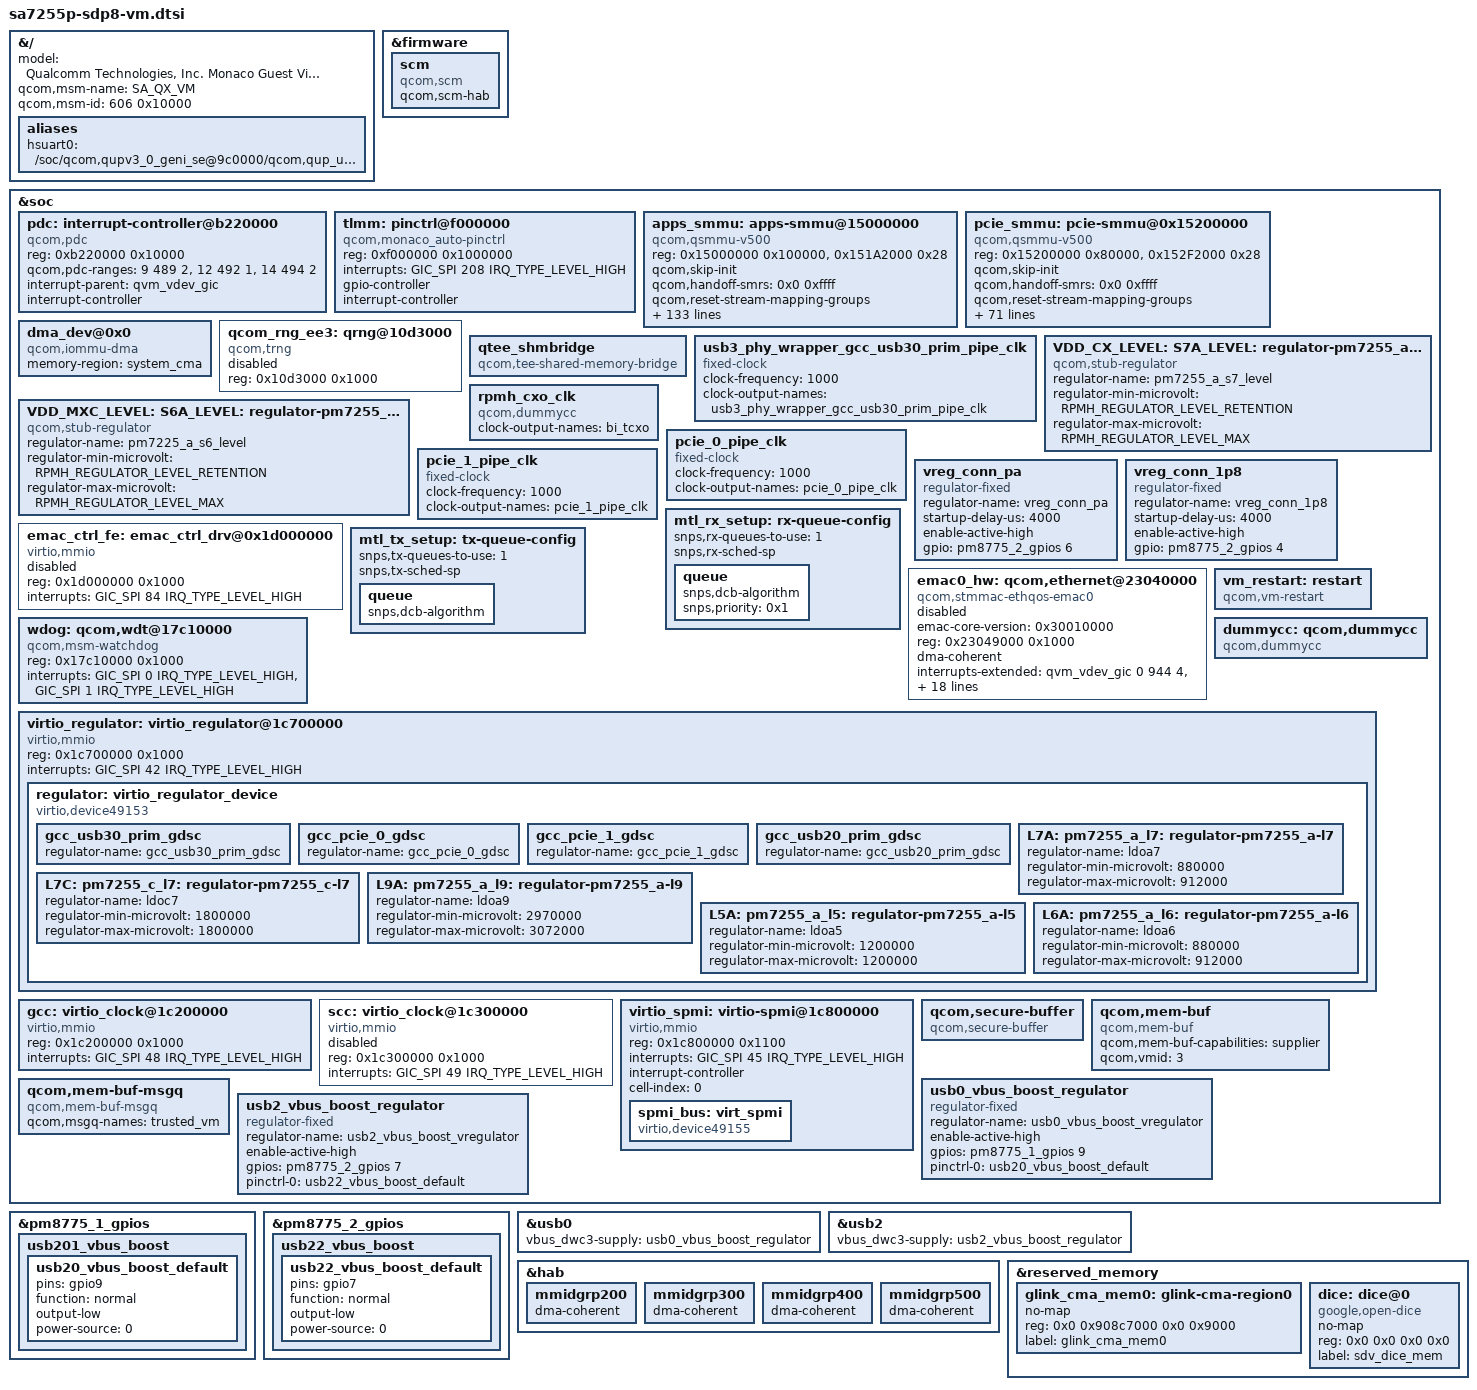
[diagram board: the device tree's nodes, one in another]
// SPDX-License-Identifier: BSD-3-Clause
/*
 * Copyright (c) Qualcomm Technologies, Inc. and/or its subsidiaries.
 */
#include "sdp8-quin-vm-common.dtsi"
#include <dt-bindings/soc/qcom,ipcc.h>

&{/} {
	model = "Qualcomm Technologies, Inc. Monaco Guest Virtual Machine";
	qcom,msm-name  = "SA_QX_VM";
	qcom,msm-id = <606 0x10000>;

	aliases {
		hsuart0 = "/soc/qcom,qupv3_0_geni_se@9c0000/qcom,qup_uart@988000";
	};
};

&firmware {
	scm: scm {
		compatible = "qcom,scm";
		qcom,scm-hab;
	};
};

&soc {
	pdc: interrupt-controller@b220000 {
		compatible = "qcom,pdc";
		reg = <0xb220000 0x10000>;
		qcom,pdc-ranges = <9 489 2>, <12 492 1>, <14 494 2>;
		#interrupt-cells = <2>;
		interrupt-parent = <&qvm_vdev_gic>;
		interrupt-controller;
	};

	tlmm: pinctrl@f000000 {
		compatible = "qcom,monaco_auto-pinctrl";
		reg = <0xf000000 0x1000000>;
		interrupts = <GIC_SPI 208 IRQ_TYPE_LEVEL_HIGH>;
		gpio-controller;
		#gpio-cells = <2>;
		interrupt-controller;
		#interrupt-cells = <2>;
	};

	apps_smmu: apps-smmu@15000000 {
		compatible = "qcom,qsmmu-v500";
		reg = <0x15000000 0x100000>,
			<0x151A2000 0x28>;
		reg-names = "base", "tcu-base";
		#iommu-cells = <2>;
		qcom,skip-init;
		qcom,handoff-smrs = <0x0 0xffff>;
		qcom,reset-stream-mapping-groups;
		qcom,multi-match-handoff-smr;
		qcom,use-3-lvl-tables;
		#global-interrupts = <2>;
		#size-cells = <1>;
		#address-cells = <1>;
		ranges;
		interrupts =	<GIC_SPI 119 IRQ_TYPE_LEVEL_HIGH>,
				<GIC_SPI 120 IRQ_TYPE_LEVEL_HIGH>,
				<GIC_SPI  98 IRQ_TYPE_LEVEL_HIGH>,
				<GIC_SPI  99 IRQ_TYPE_LEVEL_HIGH>,
				<GIC_SPI 100 IRQ_TYPE_LEVEL_HIGH>,
				<GIC_SPI 101 IRQ_TYPE_LEVEL_HIGH>,
				<GIC_SPI 102 IRQ_TYPE_LEVEL_HIGH>,
				<GIC_SPI 103 IRQ_TYPE_LEVEL_HIGH>,
				<GIC_SPI 104 IRQ_TYPE_LEVEL_HIGH>,
				<GIC_SPI 105 IRQ_TYPE_LEVEL_HIGH>,
				<GIC_SPI 106 IRQ_TYPE_LEVEL_HIGH>,
				<GIC_SPI 107 IRQ_TYPE_LEVEL_HIGH>,
				<GIC_SPI 108 IRQ_TYPE_LEVEL_HIGH>,
				<GIC_SPI 109 IRQ_TYPE_LEVEL_HIGH>,
				<GIC_SPI 110 IRQ_TYPE_LEVEL_HIGH>,
				<GIC_SPI 111 IRQ_TYPE_LEVEL_HIGH>,
				<GIC_SPI 112 IRQ_TYPE_LEVEL_HIGH>,
				<GIC_SPI 113 IRQ_TYPE_LEVEL_HIGH>,
				<GIC_SPI 114 IRQ_TYPE_LEVEL_HIGH>,
				<GIC_SPI 115 IRQ_TYPE_LEVEL_HIGH>,
				<GIC_SPI 116 IRQ_TYPE_LEVEL_HIGH>,
				<GIC_SPI 117 IRQ_TYPE_LEVEL_HIGH>,
				<GIC_SPI 118 IRQ_TYPE_LEVEL_HIGH>,
				<GIC_SPI 181 IRQ_TYPE_LEVEL_HIGH>,
				<GIC_SPI 182 IRQ_TYPE_LEVEL_HIGH>,
				<GIC_SPI 183 IRQ_TYPE_LEVEL_HIGH>,
				<GIC_SPI 184 IRQ_TYPE_LEVEL_HIGH>,
				<GIC_SPI 185 IRQ_TYPE_LEVEL_HIGH>,
				<GIC_SPI 186 IRQ_TYPE_LEVEL_HIGH>,
				<GIC_SPI 187 IRQ_TYPE_LEVEL_HIGH>,
				<GIC_SPI 188 IRQ_TYPE_LEVEL_HIGH>,
				<GIC_SPI 189 IRQ_TYPE_LEVEL_HIGH>,
				<GIC_SPI 190 IRQ_TYPE_LEVEL_HIGH>,
				<GIC_SPI 191 IRQ_TYPE_LEVEL_HIGH>,
				<GIC_SPI 192 IRQ_TYPE_LEVEL_HIGH>,
				<GIC_SPI 315 IRQ_TYPE_LEVEL_HIGH>,
				<GIC_SPI 316 IRQ_TYPE_LEVEL_HIGH>,
				<GIC_SPI 317 IRQ_TYPE_LEVEL_HIGH>,
				<GIC_SPI 318 IRQ_TYPE_LEVEL_HIGH>,
				<GIC_SPI 319 IRQ_TYPE_LEVEL_HIGH>,
				<GIC_SPI 320 IRQ_TYPE_LEVEL_HIGH>,
				<GIC_SPI 321 IRQ_TYPE_LEVEL_HIGH>,
				<GIC_SPI 322 IRQ_TYPE_LEVEL_HIGH>,
				<GIC_SPI 323 IRQ_TYPE_LEVEL_HIGH>,
				<GIC_SPI 324 IRQ_TYPE_LEVEL_HIGH>,
				<GIC_SPI 325 IRQ_TYPE_LEVEL_HIGH>,
				<GIC_SPI 326 IRQ_TYPE_LEVEL_HIGH>,
				<GIC_SPI 327 IRQ_TYPE_LEVEL_HIGH>,
				<GIC_SPI 328 IRQ_TYPE_LEVEL_HIGH>,
				<GIC_SPI 329 IRQ_TYPE_LEVEL_HIGH>,
				<GIC_SPI 330 IRQ_TYPE_LEVEL_HIGH>,
				<GIC_SPI 331 IRQ_TYPE_LEVEL_HIGH>,
				<GIC_SPI 332 IRQ_TYPE_LEVEL_HIGH>,
				<GIC_SPI 333 IRQ_TYPE_LEVEL_HIGH>,
				<GIC_SPI 334 IRQ_TYPE_LEVEL_HIGH>,
				<GIC_SPI 335 IRQ_TYPE_LEVEL_HIGH>,
				<GIC_SPI 336 IRQ_TYPE_LEVEL_HIGH>,
				<GIC_SPI 337 IRQ_TYPE_LEVEL_HIGH>,
				<GIC_SPI 338 IRQ_TYPE_LEVEL_HIGH>,
				<GIC_SPI 339 IRQ_TYPE_LEVEL_HIGH>,
				<GIC_SPI 340 IRQ_TYPE_LEVEL_HIGH>,
				<GIC_SPI 341 IRQ_TYPE_LEVEL_HIGH>,
				<GIC_SPI 342 IRQ_TYPE_LEVEL_HIGH>,
				<GIC_SPI 343 IRQ_TYPE_LEVEL_HIGH>,
				<GIC_SPI 344 IRQ_TYPE_LEVEL_HIGH>,
				<GIC_SPI 345 IRQ_TYPE_LEVEL_HIGH>,
				<GIC_SPI 395 IRQ_TYPE_LEVEL_HIGH>,
				<GIC_SPI 396 IRQ_TYPE_LEVEL_HIGH>,
				<GIC_SPI 397 IRQ_TYPE_LEVEL_HIGH>,
				<GIC_SPI 398 IRQ_TYPE_LEVEL_HIGH>,
				<GIC_SPI 399 IRQ_TYPE_LEVEL_HIGH>,
				<GIC_SPI 400 IRQ_TYPE_LEVEL_HIGH>,
				<GIC_SPI 401 IRQ_TYPE_LEVEL_HIGH>,
				<GIC_SPI 402 IRQ_TYPE_LEVEL_HIGH>,
				<GIC_SPI 403 IRQ_TYPE_LEVEL_HIGH>,
				<GIC_SPI 404 IRQ_TYPE_LEVEL_HIGH>,
				<GIC_SPI 405 IRQ_TYPE_LEVEL_HIGH>,
				<GIC_SPI 406 IRQ_TYPE_LEVEL_HIGH>,
				<GIC_SPI 407 IRQ_TYPE_LEVEL_HIGH>,
				<GIC_SPI 408 IRQ_TYPE_LEVEL_HIGH>,
				<GIC_SPI 409 IRQ_TYPE_LEVEL_HIGH>,
				<GIC_SPI 418 IRQ_TYPE_LEVEL_HIGH>,
				<GIC_SPI 419 IRQ_TYPE_LEVEL_HIGH>,
				<GIC_SPI 412 IRQ_TYPE_LEVEL_HIGH>,
				<GIC_SPI 421 IRQ_TYPE_LEVEL_HIGH>,
				<GIC_SPI 706 IRQ_TYPE_LEVEL_HIGH>,
				<GIC_SPI 423 IRQ_TYPE_LEVEL_HIGH>,
				<GIC_SPI 424 IRQ_TYPE_LEVEL_HIGH>,
				<GIC_SPI 425 IRQ_TYPE_LEVEL_HIGH>,
				<GIC_SPI 689 IRQ_TYPE_LEVEL_HIGH>,
				<GIC_SPI 690 IRQ_TYPE_LEVEL_HIGH>,
				<GIC_SPI 691 IRQ_TYPE_LEVEL_HIGH>,
				<GIC_SPI 692 IRQ_TYPE_LEVEL_HIGH>,
				<GIC_SPI 693 IRQ_TYPE_LEVEL_HIGH>,
				<GIC_SPI 694 IRQ_TYPE_LEVEL_HIGH>,
				<GIC_SPI 695 IRQ_TYPE_LEVEL_HIGH>,
				<GIC_SPI 696 IRQ_TYPE_LEVEL_HIGH>,
				<GIC_SPI 410 IRQ_TYPE_LEVEL_HIGH>,
				<GIC_SPI 411 IRQ_TYPE_LEVEL_HIGH>,
				<GIC_SPI 420 IRQ_TYPE_LEVEL_HIGH>,
				<GIC_SPI 413 IRQ_TYPE_LEVEL_HIGH>,
				<GIC_SPI 422 IRQ_TYPE_LEVEL_HIGH>,
				<GIC_SPI 707 IRQ_TYPE_LEVEL_HIGH>,
				<GIC_SPI 708 IRQ_TYPE_LEVEL_HIGH>,
				<GIC_SPI 709 IRQ_TYPE_LEVEL_HIGH>,
				<GIC_SPI 710 IRQ_TYPE_LEVEL_HIGH>,
				<GIC_SPI 711 IRQ_TYPE_LEVEL_HIGH>,
				<GIC_SPI 414 IRQ_TYPE_LEVEL_HIGH>,
				<GIC_SPI 712 IRQ_TYPE_LEVEL_HIGH>,
				<GIC_SPI 713 IRQ_TYPE_LEVEL_HIGH>,
				<GIC_SPI 714 IRQ_TYPE_LEVEL_HIGH>,
				<GIC_SPI 715 IRQ_TYPE_LEVEL_HIGH>,
				<GIC_SPI 912 IRQ_TYPE_LEVEL_HIGH>,
				<GIC_SPI 911 IRQ_TYPE_LEVEL_HIGH>,
				<GIC_SPI 910 IRQ_TYPE_LEVEL_HIGH>,
				<GIC_SPI 909 IRQ_TYPE_LEVEL_HIGH>,
				<GIC_SPI 908 IRQ_TYPE_LEVEL_HIGH>,
				<GIC_SPI 907 IRQ_TYPE_LEVEL_HIGH>,
				<GIC_SPI 906 IRQ_TYPE_LEVEL_HIGH>,
				<GIC_SPI 905 IRQ_TYPE_LEVEL_HIGH>,
				<GIC_SPI 904 IRQ_TYPE_LEVEL_HIGH>,
				<GIC_SPI 903 IRQ_TYPE_LEVEL_HIGH>,
				<GIC_SPI 902 IRQ_TYPE_LEVEL_HIGH>,
				<GIC_SPI 901 IRQ_TYPE_LEVEL_HIGH>,
				<GIC_SPI 900 IRQ_TYPE_LEVEL_HIGH>,
				<GIC_SPI 899 IRQ_TYPE_LEVEL_HIGH>,
				<GIC_SPI 898 IRQ_TYPE_LEVEL_HIGH>,
				<GIC_SPI 897 IRQ_TYPE_LEVEL_HIGH>,
				<GIC_SPI 896 IRQ_TYPE_LEVEL_HIGH>,
				<GIC_SPI 895 IRQ_TYPE_LEVEL_HIGH>;
		};

	pcie_smmu: pcie-smmu@0x15200000 {
		compatible = "qcom,qsmmu-v500";
		reg = <0x15200000 0x80000>,
			<0x152F2000 0x28>;
		reg-names = "base", "tcu-base";
		#iommu-cells = <2>;
		qcom,skip-init;
		qcom,handoff-smrs = <0x0 0xffff>;
		qcom,reset-stream-mapping-groups;
		qcom,multi-match-handoff-smr;
		qcom,use-3-lvl-tables;
		qcom,split-tables;
		#global-interrupts = <2>;
		#size-cells = <1>;
		#address-cells = <1>;
		#tcu-testbus-version = <1>;
		ranges;

		interrupts =	<GIC_SPI 920 IRQ_TYPE_LEVEL_HIGH>,
				<GIC_SPI 921 IRQ_TYPE_LEVEL_HIGH>,
				<GIC_SPI 925 IRQ_TYPE_LEVEL_HIGH>,
				<GIC_SPI 926 IRQ_TYPE_LEVEL_HIGH>,
				<GIC_SPI 927 IRQ_TYPE_LEVEL_HIGH>,
				<GIC_SPI 928 IRQ_TYPE_LEVEL_HIGH>,
				<GIC_SPI 950 IRQ_TYPE_LEVEL_HIGH>,
				<GIC_SPI 951 IRQ_TYPE_LEVEL_HIGH>,
				<GIC_SPI 952 IRQ_TYPE_LEVEL_HIGH>,
				<GIC_SPI 953 IRQ_TYPE_LEVEL_HIGH>,
				<GIC_SPI 954 IRQ_TYPE_LEVEL_HIGH>,
				<GIC_SPI 955 IRQ_TYPE_LEVEL_HIGH>,
				<GIC_SPI 956 IRQ_TYPE_LEVEL_HIGH>,
				<GIC_SPI 957 IRQ_TYPE_LEVEL_HIGH>,
				<GIC_SPI 958 IRQ_TYPE_LEVEL_HIGH>,
				<GIC_SPI 885 IRQ_TYPE_LEVEL_HIGH>,
				<GIC_SPI 886 IRQ_TYPE_LEVEL_HIGH>,
				<GIC_SPI 887 IRQ_TYPE_LEVEL_HIGH>,
				<GIC_SPI 888 IRQ_TYPE_LEVEL_HIGH>,
				<GIC_SPI 820 IRQ_TYPE_LEVEL_HIGH>,
				<GIC_SPI 822 IRQ_TYPE_LEVEL_HIGH>,
				<GIC_SPI 823 IRQ_TYPE_LEVEL_HIGH>,
				<GIC_SPI 310 IRQ_TYPE_LEVEL_HIGH>,
				<GIC_SPI 446 IRQ_TYPE_LEVEL_HIGH>,
				<GIC_SPI 447 IRQ_TYPE_LEVEL_HIGH>,
				<GIC_SPI 452 IRQ_TYPE_LEVEL_HIGH>,
				<GIC_SPI 840 IRQ_TYPE_LEVEL_HIGH>,
				<GIC_SPI 841 IRQ_TYPE_LEVEL_HIGH>,
				<GIC_SPI 842 IRQ_TYPE_LEVEL_HIGH>,
				<GIC_SPI 843 IRQ_TYPE_LEVEL_HIGH>,
				<GIC_SPI 844 IRQ_TYPE_LEVEL_HIGH>,
				<GIC_SPI 845 IRQ_TYPE_LEVEL_HIGH>,
				<GIC_SPI 846 IRQ_TYPE_LEVEL_HIGH>,
				<GIC_SPI 847 IRQ_TYPE_LEVEL_HIGH>,
				<GIC_SPI 848 IRQ_TYPE_LEVEL_HIGH>,
				<GIC_SPI 849 IRQ_TYPE_LEVEL_HIGH>,
				<GIC_SPI 802 IRQ_TYPE_LEVEL_HIGH>,
				<GIC_SPI 803 IRQ_TYPE_LEVEL_HIGH>,
				<GIC_SPI 804 IRQ_TYPE_LEVEL_HIGH>,
				<GIC_SPI 805 IRQ_TYPE_LEVEL_HIGH>,
				<GIC_SPI 806 IRQ_TYPE_LEVEL_HIGH>,
				<GIC_SPI 807 IRQ_TYPE_LEVEL_HIGH>,
				<GIC_SPI 808 IRQ_TYPE_LEVEL_HIGH>,
				<GIC_SPI 809 IRQ_TYPE_LEVEL_HIGH>,
				<GIC_SPI 810 IRQ_TYPE_LEVEL_HIGH>,
				<GIC_SPI 811 IRQ_TYPE_LEVEL_HIGH>,
				<GIC_SPI 812 IRQ_TYPE_LEVEL_HIGH>,
				<GIC_SPI 813 IRQ_TYPE_LEVEL_HIGH>,
				<GIC_SPI 814 IRQ_TYPE_LEVEL_HIGH>,
				<GIC_SPI 836 IRQ_TYPE_LEVEL_HIGH>,
				<GIC_SPI 837 IRQ_TYPE_LEVEL_HIGH>,
				<GIC_SPI 838 IRQ_TYPE_LEVEL_HIGH>,
				<GIC_SPI 839 IRQ_TYPE_LEVEL_HIGH>,
				<GIC_SPI 854 IRQ_TYPE_LEVEL_HIGH>,
				<GIC_SPI 855 IRQ_TYPE_LEVEL_HIGH>,
				<GIC_SPI 856 IRQ_TYPE_LEVEL_HIGH>,
				<GIC_SPI 790 IRQ_TYPE_LEVEL_HIGH>,
				<GIC_SPI 791 IRQ_TYPE_LEVEL_HIGH>,
				<GIC_SPI 792 IRQ_TYPE_LEVEL_HIGH>,
				<GIC_SPI 793 IRQ_TYPE_LEVEL_HIGH>,
				<GIC_SPI 794 IRQ_TYPE_LEVEL_HIGH>,
				<GIC_SPI 795 IRQ_TYPE_LEVEL_HIGH>,
				<GIC_SPI 796 IRQ_TYPE_LEVEL_HIGH>,
				<GIC_SPI 639 IRQ_TYPE_LEVEL_HIGH>,
				<GIC_SPI 79 IRQ_TYPE_LEVEL_HIGH>,
				<GIC_SPI 640 IRQ_TYPE_LEVEL_HIGH>;
	};

	dma_dev@0x0 {
		compatible = "qcom,iommu-dma";
		memory-region = <&system_cma>;
	};

	qcom_rng_ee3: qrng@10d3000 {
		compatible = "qcom,trng";
		reg = <0x10d3000 0x1000>;
		status = "disabled";
	};

	qtee_shmbridge: qtee_shmbridge {
		compatible = "qcom,tee-shared-memory-bridge";
	};

	usb3_phy_wrapper_gcc_usb30_prim_pipe_clk: usb3_phy_wrapper_gcc_usb30_prim_pipe_clk {
		compatible = "fixed-clock";
		clock-frequency = <1000>;
		clock-output-names = "usb3_phy_wrapper_gcc_usb30_prim_pipe_clk";
		#clock-cells = <0>;
	};

	VDD_CX_LEVEL: S7A_LEVEL:
		pm7255_a_s7_level: regulator-pm7255_a-s7-level {
			compatible = "qcom,stub-regulator";
			regulator-name = "pm7255_a_s7_level";
			regulator-min-microvolt =
				<RPMH_REGULATOR_LEVEL_RETENTION>;
			regulator-max-microvolt =
				<RPMH_REGULATOR_LEVEL_MAX>;
	};

	VDD_MXC_LEVEL: S6A_LEVEL:
		pm7255_a_s6_level: regulator-pm7255_a-s6-level {
			compatible = "qcom,stub-regulator";
			regulator-name = "pm7225_a_s6_level";
			regulator-min-microvolt =
				<RPMH_REGULATOR_LEVEL_RETENTION>;
			regulator-max-microvolt =
				<RPMH_REGULATOR_LEVEL_MAX>;
	};

	rpmh_cxo_clk: rpmh_cxo_clk {
		compatible = "qcom,dummycc";
		clock-output-names = "bi_tcxo";
		#clock-cells = <0>;
	};

	pcie_0_pipe_clk: pcie_0_pipe_clk {
		compatible = "fixed-clock";
		clock-frequency = <1000>;
		clock-output-names = "pcie_0_pipe_clk";
		#clock-cells = <0>;
	};

	pcie_1_pipe_clk: pcie_1_pipe_clk {
		compatible = "fixed-clock";
		clock-frequency = <1000>;
		clock-output-names = "pcie_1_pipe_clk";
		#clock-cells = <0>;
	};

	/* PWR_CTR1_VDD_PA supply */
	vreg_conn_pa: vreg_conn_pa {
		compatible = "regulator-fixed";
		regulator-name = "vreg_conn_pa";
		startup-delay-us = <4000>;
		enable-active-high;
		gpio = <&pm8775_2_gpios 6 0>;
	};

	/* PWR_CTR2_VDD_1P8 supply */
	vreg_conn_1p8: vreg_conn_1p8 {
		compatible = "regulator-fixed";
		regulator-name = "vreg_conn_1p8";
		startup-delay-us = <4000>;
		enable-active-high;
		gpio = <&pm8775_2_gpios 4 0>;
	};

	emac_ctrl_fe: emac_ctrl_drv@0x1d000000 {
		compatible = "virtio,mmio";
		reg =<0x1d000000 0x1000>;
		interrupts = <GIC_SPI 84 IRQ_TYPE_LEVEL_HIGH>;
		status = "disabled";
	};

	mtl_rx_setup: rx-queue-config {
		snps,rx-queues-to-use = <1>;
		snps,rx-sched-sp;

		queue {
			snps,dcb-algorithm;
			snps,priority = <0x1>;
		};
	};

	mtl_tx_setup: tx-queue-config {
		snps,tx-queues-to-use = <1>;
		snps,tx-sched-sp;
		queue {
			snps,dcb-algorithm;
		};
	};

	emac0_hw: qcom,ethernet@23040000 {
		compatible = "qcom,stmmac-ethqos-emac0";
		emac-core-version = <0x30010000>;
		reg = <0x23049000 0x1000>;
		reg-names = "stmmaceth";
		dma-coherent;
		interrupts-extended = <&qvm_vdev_gic 0 944 4>, <&qvm_vdev_gic 0 945 4>,
			<&qvm_vdev_gic 0 943 4>, <&qvm_vdev_gic 0 942 4>,
			<&qvm_vdev_gic 0 941 4>, <&qvm_vdev_gic 0 940 4>,
			<&qvm_vdev_gic 0 939 4>, <&qvm_vdev_gic 0 938 4>,
			<&qvm_vdev_gic 0 863 4>,<&qvm_vdev_gic 0 859 4>,
			<&qvm_vdev_gic 0 866 4>,<&qvm_vdev_gic 0 869 4>,
			<&qvm_vdev_gic 0 870 4>,<&qvm_vdev_gic 0 871 4>,
			<&qvm_vdev_gic 0 872 4>,<&qvm_vdev_gic 0 858 4>;
		interrupt-names = "tx_ch0_intr", "tx_ch1_intr",
			"tx_ch2_intr", "tx_ch3_intr",
			"tx_ch4_intr", "tx_ch5_intr",
			"tx_ch6_intr", "tx_ch7_intr",
			"rx_ch0_intr","rx_ch1_intr",
			"rx_ch2_intr","rx_ch3_intr",
			"rx_ch4_intr","rx_ch5_intr",
			"rx_ch6_intr","rx_ch7_intr";

		snps,tso;
		snps,pbl = <32>;
		mac-address = [00 55 7B B5 7D f7];
		rx-fifo-depth = <5120>;
		tx-fifo-depth = <5120>;
		snps,mtl-rx-config = <&mtl_rx_setup>;
		snps,mtl-tx-config = <&mtl_tx_setup>;
		queue = <0>;
		iommus = <&apps_smmu 0x122 0x1>;
		qcom,iommu-dma = "fastmap";
		status = "disabled";
	};

	wdog: qcom,wdt@17c10000 {
		compatible = "qcom,msm-watchdog";
		reg = <0x17c10000 0x1000>;
		reg-names = "wdt-base";
		interrupts = <GIC_SPI 0 IRQ_TYPE_LEVEL_HIGH>,
			     <GIC_SPI 1 IRQ_TYPE_LEVEL_HIGH>;
	};

	vm_restart: restart {
		compatible = "qcom,vm-restart";
		status = "ok";
	};

	dummycc: qcom,dummycc {
		compatible = "qcom,dummycc";
		#clock-cells = <1>;
		#reset-cells = <1>;
	};

	virtio_regulator: virtio_regulator@1c700000 {
		compatible = "virtio,mmio";
		reg = <0x1c700000 0x1000>;
		interrupts = <GIC_SPI 42 IRQ_TYPE_LEVEL_HIGH>;

		regulator: virtio_regulator_device {
			compatible = "virtio,device49153";	/* VIRTIO_ID: 0xC001 */
			};
	};

	gcc: virtio_clock@1c200000 {
		compatible = "virtio,mmio";
		reg = <0x1c200000 0x1000>;
		interrupts = <GIC_SPI 48 IRQ_TYPE_LEVEL_HIGH>;
		#clock-cells = <1>;
		#reset-cells = <1>;
	};

	scc: virtio_clock@1c300000 {
		compatible = "virtio,mmio";
		reg = <0x1c300000 0x1000>;
		interrupts = <GIC_SPI 49 IRQ_TYPE_LEVEL_HIGH>;
		#clock-cells = <1>;
	};

	virtio_spmi: virtio-spmi@1c800000 {
		compatible = "virtio,mmio";
		#address-cells = <1>;
		#size-cells = <1>;
		reg = <0x1c800000 0x1100>;
		interrupt-names = "periph_irq";
		interrupts = <GIC_SPI 45 IRQ_TYPE_LEVEL_HIGH>;
		interrupt-controller;
		#interrupt-cells = <4>;
		cell-index = <0>;
		status = "okay";

		spmi_bus: virt_spmi {
			compatible = "virtio,device49155"; /* VIRTIO_ID: 0xC003 */
		};
	};

	qcom,secure-buffer {
		compatible = "qcom,secure-buffer";
	};

	qcom,mem-buf {
		compatible = "qcom,mem-buf";
		qcom,mem-buf-capabilities = "supplier";
		qcom,vmid = <3>;
	};

	qcom,mem-buf-msgq {
		compatible = "qcom,mem-buf-msgq";
		qcom,msgq-names = "trusted_vm";
	};
};

#include "monaco_auto-pinctrl.dtsi"
#include "monaco-vm-usb.dtsi"
#include "pm8775-vm.dtsi"
#include "monaco-vm-qupv3.dtsi"
#include "monaco-vm-pcie.dtsi"

&regulator {
	gcc_usb30_prim_gdsc: gcc_usb30_prim_gdsc {
		regulator-name = "gcc_usb30_prim_gdsc";
	};

	gcc_pcie_0_gdsc: gcc_pcie_0_gdsc {
		regulator-name = "gcc_pcie_0_gdsc";
	};

	gcc_pcie_1_gdsc: gcc_pcie_1_gdsc {
		regulator-name = "gcc_pcie_1_gdsc";
	};

	gcc_usb20_prim_gdsc: gcc_usb20_prim_gdsc {
		regulator-name = "gcc_usb20_prim_gdsc";
	};

	L7A: pm7255_a_l7: regulator-pm7255_a-l7 {
		regulator-name = "ldoa7";
		regulator-min-microvolt = <880000>;
		regulator-max-microvolt = <912000>;
	};

	L7C: pm7255_c_l7: regulator-pm7255_c-l7 {
		regulator-name = "ldoc7";
		regulator-min-microvolt = <1800000>;
		regulator-max-microvolt = <1800000>;
	};

	L9A: pm7255_a_l9: regulator-pm7255_a-l9 {
		regulator-name = "ldoa9";
		regulator-min-microvolt = <2970000>;
		regulator-max-microvolt = <3072000>;
	};

	L5A: pm7255_a_l5: regulator-pm7255_a-l5 {
		regulator-name = "ldoa5";
		regulator-min-microvolt = <1200000>;
		regulator-max-microvolt = <1200000>;
	};

	L6A: pm7255_a_l6: regulator-pm7255_a-l6 {
		regulator-name = "ldoa6";
		regulator-min-microvolt = <880000>;
		regulator-max-microvolt = <912000>;
	};
};

&pm8775_1_gpios {
	usb201_vbus_boost {
		usb20_vbus_boost_default: usb20_vbus_boost_default {
			pins = "gpio9";
			function = "normal";
			output-low;
			power-source = <0>;
		};
	};
};

&pm8775_2_gpios {
	usb22_vbus_boost {
		usb22_vbus_boost_default: usb22_vbus_boost_default {
			pins = "gpio7";
			function = "normal";
			output-low;
			power-source = <0>;
		};
	};
};

&soc {
	usb0_vbus_boost_regulator: usb0_vbus_boost_regulator {
		compatible = "regulator-fixed";
		regulator-name = "usb0_vbus_boost_vregulator";
		enable-active-high;
		gpios = <&pm8775_1_gpios 9 0>;

		pinctrl-names = "default";
		pinctrl-0 = <&usb20_vbus_boost_default>;
	};

	usb2_vbus_boost_regulator: usb2_vbus_boost_regulator {
		compatible = "regulator-fixed";
		regulator-name = "usb2_vbus_boost_vregulator";
		enable-active-high;
		gpios = <&pm8775_2_gpios 7 0>;

		pinctrl-names = "default";
		pinctrl-0 = <&usb22_vbus_boost_default>;
	};
};

&usb0 {
	vbus_dwc3-supply = <&usb0_vbus_boost_regulator>;
};

&usb2 {
	vbus_dwc3-supply = <&usb2_vbus_boost_regulator>;
};

&scc {
	status = "disabled";
};

&hab {
	mmidgrp200: mmidgrp200 {
		dma-coherent;
	};

	mmidgrp300: mmidgrp300 {
		dma-coherent;
	};

	mmidgrp400: mmidgrp400 {
		dma-coherent;
	};

	mmidgrp500: mmidgrp500 {
		dma-coherent;
	};
};

&reserved_memory {
	glink_cma_mem0: glink-cma-region0 {
		no-map;
		reg = <0x0 0x908c7000 0x0 0x9000>;
		label = "glink_cma_mem0";
	};

	dice: dice@0 {
		compatible = "google,open-dice";
		no-map;
		reg = <0x0 0x0 0x0 0x0>;
		label = "sdv_dice_mem";
	};
};
